AUTOSAR XML (schema 4-3-0)
package /MICROSAR/Os_swc/DataTypes
  impl type TimeInMicrosecondsType: range raw 0..4294967295, implementation-data-type=uint32
  impl type CounterType: range raw 0..255, implementation-data-type=uint8, type-emitter=Os
package /MICROSAR/Os_swc/Interfaces
  client server interface Os_Service: is-service=true, service-kind=OPERATING-SYSTEM
    operation GetCounterValue: possible-error=[E_OK, E_OS_ID]  # This service reads the current count value of a counter (returning either the hardware timer ticks if counter is driven by hardware or the software ticks when user drives counter).
      arg Value: type=TimeInMicrosecondsType, direction=OUT
    operation GetElapsedValue: possible-error=[E_OK, E_OS_ID, E_OS_VALUE]  # This service gets the number of ticks between the current tick value and a previously read tick value.
      arg Value: type=TimeInMicrosecondsType, direction=INOUT
      arg ElapsedValue: type=TimeInMicrosecondsType, direction=OUT
    5 x error:
      E_OK: error-code=0
      E_OS_ACCESS: error-code=1
      E_OS_ID: error-code=3
      E_OS_STATE: error-code=7
      E_OS_VALUE: error-code=8
package /MICROSAR/Os_swc/ComponentTypes
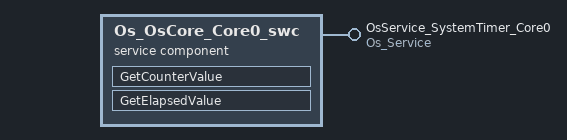
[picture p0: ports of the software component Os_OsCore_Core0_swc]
  service sw component type Os_OsCore_Core0_swc: category=SERVICE_COMPONENT
    provide port OsService_SystemTimer_Core0: provided-interface=Os_Service
    behavior Os_OsCore_Core0_swcInternalBehavior: handle-termination-and-restart=NO-SUPPORT, port-api-option{enable-take-address=true, indirect-api=false, port-defined-argument-value{value=SystemTimer_Core0, value-type=CounterType}, port=OsService_SystemTimer_Core0}
      operation invoked event OpEventGetCounterValue_GetCounterValue_OsService_SystemTimer_Core0: start-on-event=Os_OsCore_Core0_swcInternalBehavior/GetCounterValue, operation=OsService_SystemTimer_Core0.GetCounterValue
      operation invoked event OpEventGetElapsedValue_GetElapsedValue_OsService_SystemTimer_Core0: start-on-event=Os_OsCore_Core0_swcInternalBehavior/GetElapsedValue, operation=OsService_SystemTimer_Core0.GetElapsedValue
      runnable GetCounterValue: can-be-invoked-concurrently=true
      runnable GetElapsedValue: can-be-invoked-concurrently=true
  swc implementation Os_OsCore_Core0_swcImplementation: programming-language=C, behavior=Os_OsCore_Core0_swcInternalBehavior
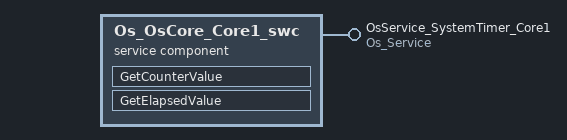
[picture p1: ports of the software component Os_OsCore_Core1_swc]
  service sw component type Os_OsCore_Core1_swc: category=SERVICE_COMPONENT
    provide port OsService_SystemTimer_Core1: provided-interface=Os_Service
    behavior Os_OsCore_Core1_swcInternalBehavior: handle-termination-and-restart=NO-SUPPORT, port-api-option{enable-take-address=true, indirect-api=false, port-defined-argument-value{value=SystemTimer_Core1, value-type=CounterType}, port=OsService_SystemTimer_Core1}
      operation invoked event OpEventGetCounterValue_GetCounterValue_OsService_SystemTimer_Core1: start-on-event=Os_OsCore_Core1_swcInternalBehavior/GetCounterValue, operation=OsService_SystemTimer_Core1.GetCounterValue
      operation invoked event OpEventGetElapsedValue_GetElapsedValue_OsService_SystemTimer_Core1: start-on-event=Os_OsCore_Core1_swcInternalBehavior/GetElapsedValue, operation=OsService_SystemTimer_Core1.GetElapsedValue
      runnable GetCounterValue: can-be-invoked-concurrently=true
      runnable GetElapsedValue: can-be-invoked-concurrently=true
  swc implementation Os_OsCore_Core1_swcImplementation: programming-language=C, behavior=Os_OsCore_Core1_swcInternalBehavior
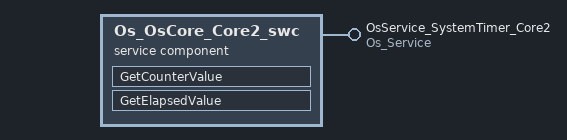
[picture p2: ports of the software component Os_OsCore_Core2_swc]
  service sw component type Os_OsCore_Core2_swc: category=SERVICE_COMPONENT
    provide port OsService_SystemTimer_Core2: provided-interface=Os_Service
    behavior Os_OsCore_Core2_swcInternalBehavior: handle-termination-and-restart=NO-SUPPORT, port-api-option{enable-take-address=true, indirect-api=false, port-defined-argument-value{value=SystemTimer_Core2, value-type=CounterType}, port=OsService_SystemTimer_Core2}
      operation invoked event OpEventGetCounterValue_GetCounterValue_OsService_SystemTimer_Core2: start-on-event=Os_OsCore_Core2_swcInternalBehavior/GetCounterValue, operation=OsService_SystemTimer_Core2.GetCounterValue
      operation invoked event OpEventGetElapsedValue_GetElapsedValue_OsService_SystemTimer_Core2: start-on-event=Os_OsCore_Core2_swcInternalBehavior/GetElapsedValue, operation=OsService_SystemTimer_Core2.GetElapsedValue
      runnable GetCounterValue: can-be-invoked-concurrently=true
      runnable GetElapsedValue: can-be-invoked-concurrently=true
  swc implementation Os_OsCore_Core2_swcImplementation: programming-language=C, behavior=Os_OsCore_Core2_swcInternalBehavior
